AUTOSAR XML (schema 00051)
standard types defined: uint8
package /Interfaces
  sender receiver interface srif1
    data de1: type=uint8, init-value=1
package /Swcs
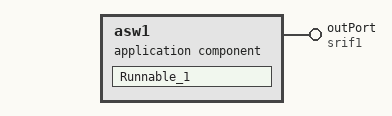
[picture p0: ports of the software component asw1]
  application sw component type asw1
    provide port outPort: provided-interface=srif1
    behavior beh1
      timing event te_5ms: period=0.005, start-on-event=Runnable_1
      runnable Runnable_1: symbol=Run1
        data-send-points:
          access dsp: accessed-variable=outPort.de1
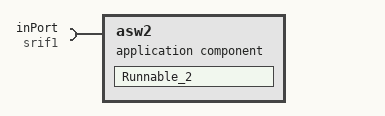
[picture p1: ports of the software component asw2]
  application sw component type asw2
    require port inPort: required-interface=srif1
    behavior beh1
      data received event DRE_Vdp: data=inPort.de1, start-on-event=Runnable_2
      runnable Runnable_2: symbol=Run2
        data-receive-point-by-arguments:
          access dra: accessed-variable=inPort.de1
  composition sw component type Comp
    component asw1_proto: type=asw1
    component asw2_proto: type=asw2
    connect asw1_proto.outPort -> asw2_proto.inPort
package /Can/signals
  i signal sig1: length=4, i-signal-type=PRIMITIVE, system-signal=syssig1
package /Can/systemsignals
  system signal syssig1
package /Can/ecus
  ecu instance ecu1: sleep-mode-supported=false, wake-up-over-bus-supported=false
package /Can/system
  system CanSystem
    system mapping Mappings: sender-receiver-to-signal-mapping{system-signal=syssig1, data-element=outPort.de1}
      sw-mappings:
        swc to ecu mapping SwcMapping: ecu-instance=ecu1, component=rootSwcom.asw1_proto.asw2_proto
    root-software-compositions:
      root sw composition prototype rootSwcom: software-composition=Comp
